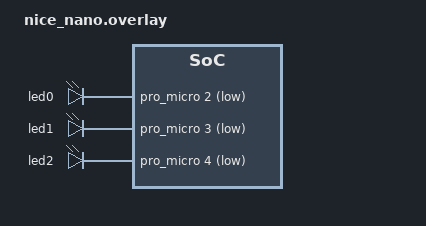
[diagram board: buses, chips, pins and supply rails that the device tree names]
/ {
    aliases {
        led-red = &led0;
        led-green = &led1;
        led-blue = &led2;
    };

    rgb_leds: leds {
        compatible = "gpio-leds";
        status = "okay";
        led0: led_0 {
            gpios = <&pro_micro 2 GPIO_ACTIVE_LOW>;
        };
        led1: led_1 {
            gpios = <&pro_micro 3 GPIO_ACTIVE_LOW>;
        };
        led2: led_2 {
            gpios = <&pro_micro 4 GPIO_ACTIVE_LOW>;
        };
    };
};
